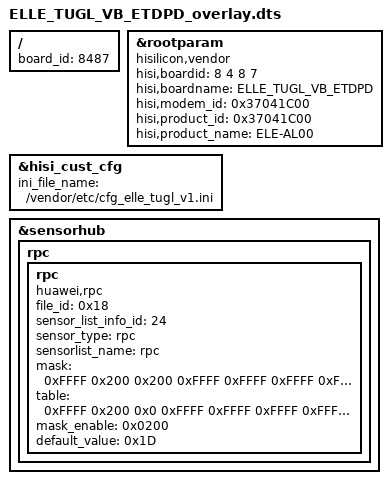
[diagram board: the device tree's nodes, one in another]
/**
 * Copyright (C) 2014 Hisilicon Ltd.
 *
 *  This program is free software; you can redistribute it and/or modify
 *  it under the terms of the GNU General Public License version 2 as
 *  publishhed by the Free Software Foundation.
 */

/dts-v1/;
/plugin/;
/include/ "ELLE_TUGL_VB_DIFEMOLD_overlay.dtsi"
/include/ "ELLE_TUGL_VB_ETDPD_pin.dtsi"
/include/ "ELLE_TUGL_VB_ETDPD_modem_pin.dtsi"

/ {
    board_id = <8487>;
};
    &rootparam{
		compatible = "hisilicon,vendor";
		hisi,boardid = <8 4 8 7>;
		hisi,boardname = "ELLE_TUGL_VB_ETDPD";
		hisi,modem_id = <0x37041C00>;
		hisi,product_id = <0x37041C00>;
		hisi,product_name = "ELE-AL00";
	};

    /*hisi customize*/
    &hisi_cust_cfg {
        ini_file_name = "/vendor/etc/cfg_elle_tugl_v1.ini";
    };
	&sensorhub{
              	rpc{
                       rpc{
                                compatible = "huawei,rpc";
                                file_id = <0x18>;
                                sensor_list_info_id = <24>;
                                sensor_type = "rpc";
                                sensorlist_name = "rpc";
                                mask = <0xFFFF 0x200 0x200 0xFFFF 0xFFFF 0xFFFF 0xFFFF 0xFFFF
                                        0xFFFF 0xFFFF 0xFFFF 0xFFFF 0xFFFF 0xFFFF 0xFFFF 0xFFFF
                                        0xFFFF 0xFFFF 0xFFFF 0xFFFF 0xFFFF 0xFFFF 0xFFFF 0xFFFF
                                        0xFFFF 0xFFFF 0xFFFF 0xFFFF 0xFFFF 0xFFFF 0xFFFF 0xFFFF>;
                                table = <0xFFFF 0x200 0x0 0xFFFF 0xFFFF 0xFFFF 0xFFFF 0xFFFF
                                         0xFFFF 0xFFFF 0xFFFF 0xFFFF 0xFFFF 0xFFFF 0xFFFF 0xFFFF
                                         0xFFFF 0xFFFF 0xFFFF 0xFFFF 0xFFFF 0xFFFF 0xFFFF 0xFFFF
                                         0xFFFF 0xFFFF 0xFFFF 0xFFFF 0xFFFF 0xFFFF 0xFFFF 0xFFFF>;
								mask_enable = <0x0200>;
								default_value = <0x1D>;
                                status = "ok";
						};
				};
	};
